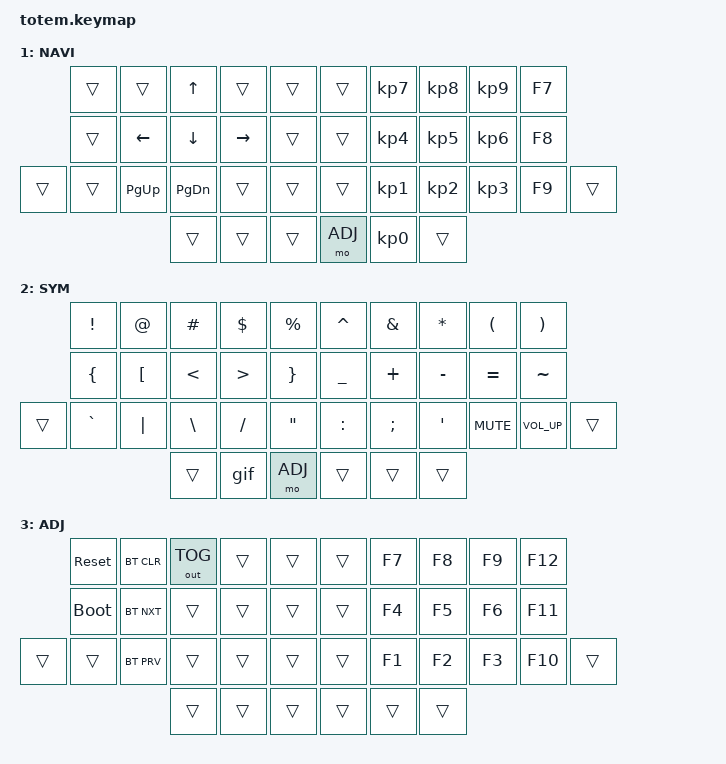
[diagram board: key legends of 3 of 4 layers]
//
//                                                        ▀▀▀▀▀     ▀▀▀▀▀          ▀▀█▀▀
//                                                        ▄▀▀▀▄  ▄  ▄▀▀▀▄  ▄  ▄▀▀▀▄  █  ▄▀▀▀▄
//                                                        █   █  █  █   █  █  █   █  █  █   █
//                                                         ▀▀▀   █   ▀▀▀   █   ▀▀▀   ▀   ▀▀▀
//                                                               █      ▄▄▄█▄▄▄    █   █  
//                                                               ▀      █  █  █     █▄█
//                                                             ▀▀▀▀▀    █  █  █      ▀
//                                                                      ▀  ▀  ▀
//
// ▄▄▄▄▄▄▄▄▄▄▄▄▄▄▄▄▄▄▄▄▄▄▄▄▄▄▄▄▄▄▄▄▄▄▄▄▄▄▄▄▄▄▄▄▄▄▄▄▄▄▄▄▄▄▄▄▄▄▄▄▄▄▄▄▄▄▄▄▄▄▄▄▄▄▄▄▄▄▄▄▄▄▄▄▄▄▄▄▄▄▄▄▄▄▄▄▄▄▄▄▄▄▄▄▄▄▄▄▄▄▄▄▄▄▄▄▄▄▄▄▄▄▄▄▄▄▄▄▄▄▄▄▄▄▄▄▄▄▄▄▄▄▄▄▄▄▄▄▄
       

#include <behaviors.dtsi>
#include <dt-bindings/zmk/keys.h>
#include <dt-bindings/zmk/bt.h>
#include <dt-bindings/zmk/outputs.h>

#define BASE 0
#define NAV  1
#define SYM  2
#define ADJ  3

&mt {
  quick-tap-ms = <100>;
  global-quick-tap;
  flavor = "tap-preferred";
  tapping-term-ms = <170>;
};

/ {
    combos {
            compatible = "zmk,combos";
            combo_esc {
                timeout-ms = <50>;
                key-positions = <0 1>;
                bindings = <&kp ESC>;
            };
    };

    macros {
        gif: gif {
            label = "giphy";
            compatible = "zmk,behavior-macro";
            #binding-cells = <0>;
            bindings
                = <&macro_press &kp LSHFT>
                , <&macro_tap &kp N2>
                , <&macro_release &kp LSHFT>
                , <&macro_tap &kp G &kp I &kp F>
                ;
        };
    };

        keymap {
                compatible = "zmk,keymap";
// ▄▄▄▄▄▄▄▄▄▄▄▄▄▄▄▄▄▄▄▄▄▄▄▄▄▄▄▄▄▄▄▄▄▄▄▄▄▄▄▄▄▄▄▄▄▄▄▄▄▄▄▄▄▄▄▄▄▄▄▄▄▄▄▄▄▄▄▄▄▄▄▄▄▄▄▄▄▄▄▄▄▄▄▄▄▄▄▄▄▄▄▄▄▄▄▄▄▄▄▄▄▄▄▄▄▄▄▄▄▄▄▄▄▄▄▄▄▄▄▄▄▄▄▄▄▄▄▄▄▄▄▄▄▄▄▄▄▄▄▄▄▄▄▄▄▄▄▄▄

                base_layer {
// ┏━━━━━━━━━━━━━━━━━━━━━━━━━━━━━━━━━━━━━━━┓
label= "BASE"                              ;
// ┗━━━━━━━━━━━━━━━━━━━━━━━━━━━━━━━━━━━━━━━┛
//             ┏━━━━━━━━━━━┳━━━━━━━━━━━┳━━━━━━━━━━━┳━━━━━━━━━━━┳━━━━━━━━━━━┓   ┏━━━━━━━━━━━┳━━━━━━━━━━━┳━━━━━━━━━━━┳━━━━━━━━━━━┳━━━━━━━━━━━┓
//             ┃     Q     ┃     W     ┃     F     ┃     P     ┃     G     ┃   ┃     J     ┃     L     ┃     U     ┃     Y     ┃     ;     ┃
//             ┣━━━━━━━━━━━╋━━━━━━━━━━━╋━━━━━━━━━━━╋━━━━━━━━━━━╋━━━━━━━━━━━┫   ┣━━━━━━━━━━━╋━━━━━━━━━━━╋━━━━━━━━━━━╋━━━━━━━━━━━╋━━━━━━━━━━━┫
//             ┃     A     ┃     R     ┃     S     ┃     T     ┃     D     ┃   ┃     H     ┃     N     ┃     E     ┃     I     ┃     O     ┃
// ┏━━━━━━━━━━━╋━━━━━━━━━━━╋━━━━━━━━━━━╋━━━━━━━━━━━╋━━━━━━━━━━━╋━━━━━━━━━━━┫   ┣━━━━━━━━━━━╋━━━━━━━━━━━╋━━━━━━━━━━━╋━━━━━━━━━━━╋━━━━━━━━━━━╋━━━━━━━━━━━┓
// ┃           ┃     Z     ┃     X     ┃     C     ┃     V     ┃     B     ┃   ┃     K     ┃     M     ┃     ,     ┃     .     ┃     /     ┃           ┃
// ┗━━━━━━━━━━━┻━━━━━━━━━━━┻━━━━━━━━━━━╋━━━━━━━━━━━╋━━━━━━━━━━━╋━━━━━━━━━━━┫   ┣━━━━━━━━━━━╋━━━━━━━━━━━╋━━━━━━━━━━━╋━━━━━━━━━━━┻━━━━━━━━━━━┻━━━━━━━━━━━┛
//                                     ┃           ┃    TAB    ┃    SPC    ┃   ┃   ENTER   ┃   BSPC    ┃           ┃
//                                     ┗━━━━━━━━━━━┻━━━━━━━━━━━┻━━━━━━━━━━━┛   ┗━━━━━━━━━━━┻━━━━━━━━━━━┻━━━━━━━━━━━┛
 bindings = <
// ╷           ╷           ╷           ╷           ╷           ╷           ╷   ╷           ╷           ╷           ╷           ╷           ╷           ╷

                &kp Q       &kp W       &kp F       &kp P       &kp G           &kp J       &kp L       &kp U       &kp Y       &kp SEMI
                &mt LGUI A  &mt LALT R  &mt LCTRL S &mt LSHFT T &kp D           &kp H       &mt RSHFT N &mt RCTRL E &mt RALT I  &mt RGUI O
    &kp Z       &kp X       &kp C       &kp V       &kp B                       &kp K       &kp M       &kp COMMA   &kp DOT     &kp FSLH    &trans
                                        &kp TAB     &lt NAV SPACE &lt SYM RET     &kp ENTER   &kp BSPC    &trans
                        >;
                };

// ▄▄▄▄▄▄▄▄▄▄▄▄▄▄▄▄▄▄▄▄▄▄▄▄▄▄▄▄▄▄▄▄▄▄▄▄▄▄▄▄▄▄▄▄▄▄▄▄▄▄▄▄▄▄▄▄▄▄▄▄▄▄▄▄▄▄▄▄▄▄▄▄▄▄▄▄▄▄▄▄▄▄▄▄▄▄▄▄▄▄▄▄▄▄▄▄▄▄▄▄▄▄▄▄▄▄▄▄▄▄▄▄▄▄▄▄▄▄▄▄▄▄▄▄▄▄▄▄▄▄▄▄▄▄▄▄▄▄▄▄▄▄▄▄▄▄▄▄▄


                nav_layer {
// ┏━━━━━━━━━━━━━━━━━━━━━━━━━━━━━━━━━━━━━━━┓
label= "NAVI"                              ;
// ┗━━━━━━━━━━━━━━━━━━━━━━━━━━━━━━━━━━━━━━━┛
//             ┏━━━━━━━━━━━┳━━━━━━━━━━━┳━━━━━━━━━━━┳━━━━━━━━━━━┳━━━━━━━━━━━┓   ┏━━━━━━━━━━━┳━━━━━━━━━━━┳━━━━━━━━━━━┳━━━━━━━━━━━┳━━━━━━━━━━━┓
//             ┃           ┃           ┃     UP    ┃           ┃           ┃   ┃           ┃     7     ┃     8     ┃     9     ┃    F7     ┃
//             ┣━━━━━━━━━━━╋━━━━━━━━━━━╋━━━━━━━━━━━╋━━━━━━━━━━━╋━━━━━━━━━━━┫   ┣━━━━━━━━━━━╋━━━━━━━━━━━╋━━━━━━━━━━━╋━━━━━━━━━━━╋━━━━━━━━━━━┫
//             ┃           ┃   LEFT    ┃    DOWN   ┃   RIGHT   ┃           ┃   ┃           ┃     4     ┃     5     ┃     6     ┃    F8     ┃
// ┏━━━━━━━━━━━╋━━━━━━━━━━━╋━━━━━━━━━━━╋━━━━━━━━━━━╋━━━━━━━━━━━╋━━━━━━━━━━━┫   ┣━━━━━━━━━━━╋━━━━━━━━━━━╋━━━━━━━━━━━╋━━━━━━━━━━━╋━━━━━━━━━━━╋━━━━━━━━━━━┓
// ┃           ┃           ┃   PG_UP   ┃   PG_DN   ┃           ┃           ┃   ┃           ┃     1     ┃     2     ┃     3     ┃    F9     ┃           ┃
// ┗━━━━━━━━━━━┻━━━━━━━━━━━┻━━━━━━━━━━━╋━━━━━━━━━━━╋━━━━━━━━━━━╋━━━━━━━━━━━┫   ┣━━━━━━━━━━━╋━━━━━━━━━━━╋━━━━━━━━━━━╋━━━━━━━━━━━┻━━━━━━━━━━━┻━━━━━━━━━━━┛
//                                     ┃           ┃           ┃           ┃   ┃           ┃     0     ┃           ┃
//                                     ┗━━━━━━━━━━━┻━━━━━━━━━━━┻━━━━━━━━━━━┛   ┗━━━━━━━━━━━┻━━━━━━━━━━━┻━━━━━━━━━━━┛
 bindings = <
// ╷           ╷           ╷           ╷           ╷           ╷           ╷   ╷           ╷           ╷           ╷           ╷           ╷           ╷

                &trans      &trans      &kp UP      &trans      &trans          &trans      &kp KP_N7   &kp KP_N8   &kp KP_N9   &kp F7
                &trans      &kp LEFT    &kp DOWN    &kp RIGHT   &trans          &trans      &kp KP_N4   &kp KP_N5   &kp KP_N6   &kp F8
    &trans      &trans      &kp PG_UP   &kp PG_DN   &trans      &trans          &trans      &kp KP_N1   &kp KP_N2   &kp KP_N3   &kp F9      &trans
                                        &trans      &trans      &trans          &mo ADJ     &kp KP_N0   &trans
                        >;
                };

// ▄▄▄▄▄▄▄▄▄▄▄▄▄▄▄▄▄▄▄▄▄▄▄▄▄▄▄▄▄▄▄▄▄▄▄▄▄▄▄▄▄▄▄▄▄▄▄▄▄▄▄▄▄▄▄▄▄▄▄▄▄▄▄▄▄▄▄▄▄▄▄▄▄▄▄▄▄▄▄▄▄▄▄▄▄▄▄▄▄▄▄▄▄▄▄▄▄▄▄▄▄▄▄▄▄▄▄▄▄▄▄▄▄▄▄▄▄▄▄▄▄▄▄▄▄▄▄▄▄▄▄▄▄▄▄▄▄▄▄▄▄▄▄▄▄▄▄▄▄


                sym_layer {
// ┏━━━━━━━━━━━━━━━━━━━━━━━━━━━━━━━━━━━━━━━┓
label= "SYM"                               ;
// ┗━━━━━━━━━━━━━━━━━━━━━━━━━━━━━━━━━━━━━━━┛
//             ┏━━━━━━━━━━━┳━━━━━━━━━━━┳━━━━━━━━━━━┳━━━━━━━━━━━┳━━━━━━━━━━━┓   ┏━━━━━━━━━━━┳━━━━━━━━━━━┳━━━━━━━━━━━┳━━━━━━━━━━━┳━━━━━━━━━━━┓
//             ┃     !     ┃     @     ┃     #     ┃     $     ┃     %     ┃   ┃     ^     ┃     &     ┃     * ┃     (     ┃     )     ┃
//             ┣━━━━━━━━━━━╋━━━━━━━━━━━╋━━━━━━━━━━━╋━━━━━━━━━━━╋━━━━━━━━━━━┫   ┣━━━━━━━━━━━╋━━━━━━━━━━━╋━━━━━━━━━━━╋━━━━━━━━━━━╋━━━━━━━━━━━┫
//             ┃     {     ┃     [     ┃     <     ┃     >     ┃     }     ┃   ┃     _     ┃     +     ┃     -     ┃     =     ┃     ~     ┃
// ┏━━━━━━━━━━━╋━━━━━━━━━━━╋━━━━━━━━━━━╋━━━━━━━━━━━╋━━━━━━━━━━━╋━━━━━━━━━━━┫   ┣━━━━━━━━━━━╋━━━━━━━━━━━╋━━━━━━━━━━━╋━━━━━━━━━━━╋━━━━━━━━━━━╋━━━━━━━━━━━┓
// ┃           ┃     `     ┃     |     ┃     \     ┃     /     ┃     "     ┃   ┃     :     ┃     ;     ┃     '     ┃  MUTE     ┃  VOL_UP   ┃           ┃
// ┗━━━━━━━━━━━┻━━━━━━━━━━━┻━━━━━━━━━━━╋━━━━━━━━━━━╋━━━━━━━━━━━╋━━━━━━━━━━━┫   ┣━━━━━━━━━━━╋━━━━━━━━━━━╋━━━━━━━━━━━╋━━━━━━━━━━━┻━━━━━━━━━━━┻━━━━━━━━━━━┛
//                                     ┃           ┃           ┃    ADJ    ┃   ┃           ┃           ┃           ┃
//                                     ┗━━━━━━━━━━━┻━━━━━━━━━━━┻━━━━━━━━━━━┛   ┗━━━━━━━━━━━┻━━━━━━━━━━━┻━━━━━━━━━━━┛
 bindings = <
// ╷           ╷           ╷           ╷           ╷           ╷           ╷   ╷           ╷           ╷           ╷           ╷           ╷           ╷

                &kp EXCL    &kp AT      &kp HASH    &kp DLLR    &kp PRCNT       &kp CARET   &kp AMPS    &kp STAR    &kp LPAR    &kp RPAR
                &kp LBRC    &kp LBKT    &kp LT      &kp GT      &kp RBRC        &kp UNDERSCORE &kp PLUS &kp MINUS   &kp EQUAL   &kp TILDE
    &trans      &kp GRAVE   &kp PIPE    &kp BSLH    &kp FSLH    &kp DQT         &kp COLON   &kp SEMI    &kp SQT     &kp C_MUTE  &kp C_VOL_UP &trans
                                        &trans      &gif        &mo ADJ         &trans      &trans      &trans
                        >;
                };

// ▄▄▄▄▄▄▄▄▄▄▄▄▄▄▄▄▄▄▄▄▄▄▄▄▄▄▄▄▄▄▄▄▄▄▄▄▄▄▄▄▄▄▄▄▄▄▄▄▄▄▄▄▄▄▄▄▄▄▄▄▄▄▄▄▄▄▄▄▄▄▄▄▄▄▄▄▄▄▄▄▄▄▄▄▄▄▄▄▄▄▄▄▄▄▄▄▄▄▄▄▄▄▄▄▄▄▄▄▄▄▄▄▄▄▄▄▄▄▄▄▄▄▄▄▄▄▄▄▄▄▄▄▄▄▄▄▄▄▄▄▄▄▄▄▄▄▄▄▄


                adjust_layer {
// ┏━━━━━━━━━━━━━━━━━━━━━━━━━━━━━━━━━━━━━━━┓
label= "ADJ"                               ;
// ┗━━━━━━━━━━━━━━━━━━━━━━━━━━━━━━━━━━━━━━━┛
//             ┏━━━━━━━━━━━┳━━━━━━━━━━━┳━━━━━━━━━━━┳━━━━━━━━━━━┳━━━━━━━━━━━┓   ┏━━━━━━━━━━━┳━━━━━━━━━━━┳━━━━━━━━━━━┳━━━━━━━━━━━┳━━━━━━━━━━━┓
//             ┃   RESET   ┃ BT_CLR    ┃ OUT_TOG   ┃           ┃           ┃   ┃           ┃    F7     ┃    F8     ┃    F9     ┃    F12    ┃
//             ┣━━━━━━━━━━━╋━━━━━━━━━━━╋━━━━━━━━━━━╋━━━━━━━━━━━╋━━━━━━━━━━━┫   ┣━━━━━━━━━━━╋━━━━━━━━━━━╋━━━━━━━━━━━╋━━━━━━━━━━━╋━━━━━━━━━━━┫
//             ┃ BOOTLOAD  ┃ BT_NXT    ┃           ┃           ┃           ┃   ┃           ┃    F4     ┃    F5     ┃    F6     ┃    F11    ┃
// ┏━━━━━━━━━━━╋━━━━━━━━━━━╋━━━━━━━━━━━╋━━━━━━━━━━━╋━━━━━━━━━━━╋━━━━━━━━━━━┫   ┣━━━━━━━━━━━╋━━━━━━━━━━━╋━━━━━━━━━━━╋━━━━━━━━━━━╋━━━━━━━━━━━╋━━━━━━━━━━━┓
// ┃           ┃           ┃ BT_PRV    ┃           ┃           ┃           ┃   ┃           ┃    F1     ┃    F2     ┃    F3     ┃    F10    ┃           ┃
// ┗━━━━━━━━━━━┻━━━━━━━━━━━┻━━━━━━━━━━━╋━━━━━━━━━━━╋━━━━━━━━━━━╋━━━━━━━━━━━┫   ┣━━━━━━━━━━━╋━━━━━━━━━━━╋━━━━━━━━━━━╋━━━━━━━━━━━┻━━━━━━━━━━━┻━━━━━━━━━━━┛
//                                     ┃           ┃           ┃           ┃   ┃           ┃           ┃           ┃
//                                     ┗━━━━━━━━━━━┻━━━━━━━━━━━┻━━━━━━━━━━━┛   ┗━━━━━━━━━━━┻━━━━━━━━━━━┻━━━━━━━━━━━┛
 bindings = <
// ╷           ╷           ╷           ╷           ╷           ╷           ╷   ╷           ╷           ╷           ╷           ╷           ╷           ╷

                &sys_reset  &bt BT_CLR  &out OUT_TOG &trans      &trans          &trans      &kp F7      &kp F8      &kp F9      &kp F12
                &bootloader &bt BT_NXT  &trans      &trans      &trans          &trans      &kp F4      &kp F5      &kp F6      &kp F11
    &trans      &trans      &bt BT_PRV  &trans      &trans      &trans          &trans      &kp F1      &kp F2      &kp F3      &kp F10     &trans
                                        &trans      &trans      &trans          &trans      &trans      &trans
                        >;
                };
        };
};

